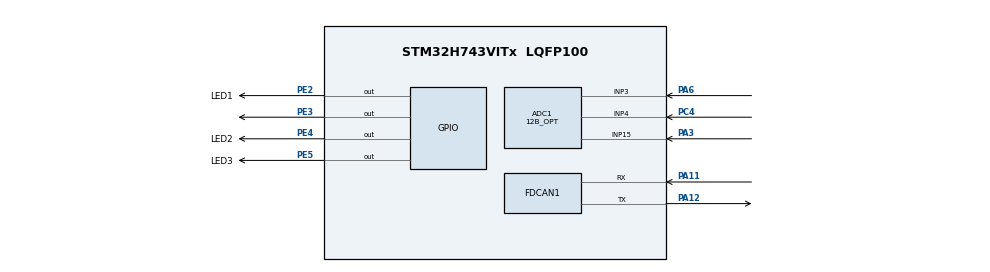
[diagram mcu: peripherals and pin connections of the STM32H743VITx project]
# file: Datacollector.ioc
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ADC1.Channel-1\#ChannelRegularConversion=ADC_CHANNEL_3
ADC1.Channel-7\#ChannelRegularConversion=ADC_CHANNEL_4
ADC1.Channel-8\#ChannelRegularConversion=ADC_CHANNEL_15
ADC1.ClockPrescaler=ADC_CLOCK_ASYNC_DIV1
ADC1.ContinuousConvMode=DISABLE
ADC1.ConversionDataManagement=ADC_CONVERSIONDATA_DMA_ONESHOT
ADC1.DiscontinuousConvMode=DISABLE
ADC1.EOCSelection=ADC_EOC_SEQ_CONV
ADC1.EnableAnalogWatchDog1=false
ADC1.ExternalTrigConv=ADC_SOFTWARE_START
ADC1.NbrOfConversion=3
ADC1.NbrOfConversionFlag=1
ADC1.OffsetNumber-1\#ChannelRegularConversion=ADC_OFFSET_NONE
ADC1.OffsetNumber-7\#ChannelRegularConversion=ADC_OFFSET_NONE
ADC1.OffsetNumber-8\#ChannelRegularConversion=ADC_OFFSET_NONE
ADC1.OffsetSignedSaturation-1\#ChannelRegularConversion=DISABLE
ADC1.Rank-1\#ChannelRegularConversion=1
ADC1.Rank-7\#ChannelRegularConversion=2
ADC1.Rank-8\#ChannelRegularConversion=3
ADC1.Resolution=ADC_RESOLUTION_12B_OPT
ADC1.SamplingTime-1\#ChannelRegularConversion=ADC_SAMPLETIME_1CYCLE_5
ADC1.SamplingTime-7\#ChannelRegularConversion=ADC_SAMPLETIME_2CYCLES_5
ADC1.SamplingTime-8\#ChannelRegularConversion=ADC_SAMPLETIME_8CYCLES_5
ADC1.master=1
Dma.ADC1.0.Direction=DMA_PERIPH_TO_MEMORY
Dma.ADC1.0.EventEnable=DISABLE
Dma.ADC1.0.FIFOMode=DMA_FIFOMODE_DISABLE
Dma.ADC1.0.Instance=DMA1_Stream0
Dma.ADC1.0.MemDataAlignment=DMA_MDATAALIGN_WORD
Dma.ADC1.0.MemInc=DMA_MINC_ENABLE
Dma.ADC1.0.Mode=DMA_CIRCULAR
Dma.ADC1.0.PeriphDataAlignment=DMA_PDATAALIGN_WORD
Dma.ADC1.0.PeriphInc=DMA_PINC_DISABLE
Dma.ADC1.0.Polarity=HAL_DMAMUX_REQ_GEN_RISING
Dma.ADC1.0.Priority=DMA_PRIORITY_LOW
Dma.ADC1.0.RequestNumber=1
Dma.ADC1.0.SignalID=NONE
Dma.ADC1.0.SyncEnable=DISABLE
Dma.ADC1.0.SyncPolarity=HAL_DMAMUX_SYNC_NO_EVENT
Dma.ADC1.0.SyncRequestNumber=1
Dma.ADC1.0.SyncSignalID=NONE
Dma.Request0=ADC1
FDCAN1.AutoRetransmission=DISABLE
FDCAN1.ClockCalibrationCCU=DISABLE
FDCAN1.DataPrescaler=1
FDCAN1.DataSyncJumpWidth=2
FDCAN1.DataTimeSeg1=13
FDCAN1.DataTimeSeg2=2
FDCAN1.FrameFormat=FDCAN_FRAME_CLASSIC
FDCAN1.NominalSyncJumpWidth=2
FDCAN1.NominalTimeSeg1=\ 13
FDCAN1.RxBuffersNbr=32
FDCAN1.RxFifo0ElmtSize=FDCAN_DATA_BYTES_8
FDCAN1.RxFifo0ElmtsNbr=32
FDCAN1.RxFifo1ElmtsNbr=32
FDCAN1.StdFiltersNbr=0
FDCAN1.TxBuffersNbr=32
FDCAN1.TxElmtSize=FDCAN_DATA_BYTES_8
FDCAN1.TxEventsNbr=32
FDCAN1.TxFifoQueueElmtsNbr=32
Mcu.Family=STM32H7
Mcu.Name=STM32H743VITx
Mcu.Package=LQFP100
NVIC.DMA1_Stream0_IRQn=true\:0\:0\:false\:false\:true\:false\:true\:true
NVIC.FDCAN1_IT0_IRQn=true\:5\:0\:true\:false\:true\:true\:true\:true
NVIC.FDCAN1_IT1_IRQn=true\:0\:0\:false\:false\:true\:true\:true\:true
NVIC.PriorityGroup=NVIC_PRIORITYGROUP_4
NVIC.TIM1_UP_IRQn=true\:0\:0\:false\:false\:true\:true\:true\:true
PA11.Mode=FDCAN_Activate
PA11.Signal=FDCAN1_RX
PA12.Mode=FDCAN_Activate
PA12.Signal=FDCAN1_TX
PA13\ (JTMS/SWDIO).Mode=Serial_Wire
PA13\ (JTMS/SWDIO).Signal=DEBUG_JTMS-SWDIO
PA14\ (JTCK/SWCLK).Mode=Serial_Wire
PA14\ (JTCK/SWCLK).Signal=DEBUG_JTCK-SWCLK
PA3.Signal=ADCx_INP15
PA6.Signal=ADCx_INP3
PC4.Signal=ADCx_INP4
PE2.GPIO_Label=LED1
PE2.Signal=GPIO_Output
PE3.Signal=GPIO_Output
PE4.GPIO_Label=LED2
PE4.Signal=GPIO_Output
PE5.GPIO_Label=LED3
PE5.Signal=GPIO_Output
PH0-OSC_IN\ (PH0).Mode=HSE-External-Oscillator
PH0-OSC_IN\ (PH0).Signal=RCC_OSC_IN
PH1-OSC_OUT\ (PH1).Mode=HSE-External-Oscillator
PH1-OSC_OUT\ (PH1).Signal=RCC_OSC_OUT
ProjectManager.HeapSize=0x200
ProjectManager.StackSize=0x400
ProjectManager.TargetToolchain=STM32CubeIDE
RCC.ADCFreq_Value=40000000
RCC.APB1Freq_Value=50000000
RCC.APB2Freq_Value=100000000
RCC.APB3Freq_Value=50000000
RCC.APB4Freq_Value=100000000
RCC.CortexFreq_Value=100000000
RCC.D1CPRE=RCC_SYSCLK_DIV2
RCC.D1PPRE=RCC_APB3_DIV2
RCC.D2PPRE1=RCC_APB1_DIV2
RCC.DIVM1=1
RCC.DIVM2=4
RCC.DIVM3=22
RCC.DIVN1=50
RCC.DIVN2=80
RCC.DIVP2=4
RCC.DIVQ1=8
RCC.DIVQ2=5
RCC.DIVR1=10
RCC.FDCANCLockSelection=RCC_FDCANCLKSOURCE_HSE
RCC.HCLKFreq_Value=100000000
RCC.HSE_VALUE=8000000
RCC.PLL2FRACN=0
RCC.PLLFRACN=0
RCC.PLLSourceVirtual=RCC_PLLSOURCE_HSE
RCC.PREFETCH_ENABLE=1
RCC.SYSCLKFreq_VALUE=200000000
RCC.SYSCLKSource=RCC_SYSCLKSOURCE_PLLCLK
RCC.USBFreq_Value=50000000
SH.ADCx_INP15.0=ADC1_INP15,IN15-Single-Ended
SH.ADCx_INP3.0=ADC1_INP3,IN3-Single-Ended
SH.ADCx_INP4.0=ADC1_INP4,IN4-Single-Ended
TIM1.AutoReloadPreload=TIM_AUTORELOAD_PRELOAD_DISABLE
TIM1.Period=1
TIM1.Prescaler=10000
TIM1.RepetitionCounter=0
TIM1.TIM_MasterOutputTrigger=TIM_TRGO_UPDATE
VP_TIM1_VS_ClockSourceINT.Mode=Internal
board=custom

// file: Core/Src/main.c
/* USER CODE BEGIN Header */
/**
 ******************************************************************************
 * @file           : main.c
 * @brief          : Main program body
 ******************************************************************************
 * @attention
 *
 * Copyright (c) 2023 STMicroelectronics.
 * All rights reserved.
 *
 * This software is licensed under terms that can be found in the LICENSE file
 * in the root directory of this software component.
 * If no LICENSE file comes with this software, it is provided AS-IS.
 *
 ******************************************************************************
 */
/* USER CODE END Header */
#include "main.h"

/* USER CODE BEGIN Includes */
#include "CAN.h"
#include "ADC.h"
/* USER CODE END Includes */

 ADC_HandleTypeDef hadc1;
DMA_HandleTypeDef hdma_adc1;

FDCAN_HandleTypeDef hfdcan1;

TIM_HandleTypeDef htim1;

/* USER CODE BEGIN PV */
ADC_ChannelConfTypeDef sConfig = { 0 };
uint16_t TxData[4];
extern uint32_t ADC_value[3];
/* USER CODE END PV */

void SystemClock_Config(void);
static void MX_GPIO_Init(void);
static void MX_DMA_Init(void);
static void MX_ADC1_Init(void);
static void MX_TIM1_Init(void);
static void MX_FDCAN1_Init(void);

int main(void)
{

  /* MCU Configuration--------------------------------------------------------*/

  /* Reset of all peripherals, Initializes the Flash interface and the Systick. */
  HAL_Init();

  /* Configure the system clock */
  SystemClock_Config();

  /* Initialize all configured peripherals */
  MX_GPIO_Init();
  MX_DMA_Init();
  MX_ADC1_Init();
  MX_TIM1_Init();
  MX_FDCAN1_Init();
  /* USER CODE BEGIN 2 */
	ADC_Init();
	CAN_Init();
  /* USER CODE END 2 */

  /* Infinite loop */
	while (1) {

    /* USER CODE BEGIN 3 */
		HAL_GPIO_TogglePin(LED1_GPIO_Port, LED1_Pin);
		TxData[0] = ADC_value[0];
		CAN_TxData(101, TxData);
		HAL_Delay(50);
	}
  /* USER CODE END 3 */
}

void SystemClock_Config(void)
{
  RCC_OscInitTypeDef RCC_OscInitStruct = {0};
  RCC_ClkInitTypeDef RCC_ClkInitStruct = {0};

  /** Supply configuration update enable
  */
  HAL_PWREx_ConfigSupply(PWR_LDO_SUPPLY);

  /** Configure the main internal regulator output voltage
  */
  __HAL_PWR_VOLTAGESCALING_CONFIG(PWR_REGULATOR_VOLTAGE_SCALE3);

  while(!__HAL_PWR_GET_FLAG(PWR_FLAG_VOSRDY)) {}

  /** Macro to configure the PLL clock source
  */
  __HAL_RCC_PLL_PLLSOURCE_CONFIG(RCC_PLLSOURCE_HSE);

  /** Initializes the RCC Oscillators according to the specified parameters
  * in the RCC_OscInitTypeDef structure.
  */
  RCC_OscInitStruct.OscillatorType = RCC_OSCILLATORTYPE_HSE;
  RCC_OscInitStruct.HSEState = RCC_HSE_ON;
  RCC_OscInitStruct.PLL.PLLState = RCC_PLL_ON;
  RCC_OscInitStruct.PLL.PLLSource = RCC_PLLSOURCE_HSE;
  RCC_OscInitStruct.PLL.PLLM = 1;
  RCC_OscInitStruct.PLL.PLLN = 50;
  RCC_OscInitStruct.PLL.PLLP = 2;
  RCC_OscInitStruct.PLL.PLLQ = 8;
  RCC_OscInitStruct.PLL.PLLR = 10;
  RCC_OscInitStruct.PLL.PLLRGE = RCC_PLL1VCIRANGE_3;
  RCC_OscInitStruct.PLL.PLLVCOSEL = RCC_PLL1VCOWIDE;
  RCC_OscInitStruct.PLL.PLLFRACN = 0;
  if (HAL_RCC_OscConfig(&RCC_OscInitStruct) != HAL_OK)
  {
    Error_Handler();
  }

  /** Initializes the CPU, AHB and APB buses clocks
  */
  RCC_ClkInitStruct.ClockType = RCC_CLOCKTYPE_HCLK|RCC_CLOCKTYPE_SYSCLK
                              |RCC_CLOCKTYPE_PCLK1|RCC_CLOCKTYPE_PCLK2
                              |RCC_CLOCKTYPE_D3PCLK1|RCC_CLOCKTYPE_D1PCLK1;
  RCC_ClkInitStruct.SYSCLKSource = RCC_SYSCLKSOURCE_PLLCLK;
  RCC_ClkInitStruct.SYSCLKDivider = RCC_SYSCLK_DIV2;
  RCC_ClkInitStruct.AHBCLKDivider = RCC_HCLK_DIV1;
  RCC_ClkInitStruct.APB3CLKDivider = RCC_APB3_DIV2;
  RCC_ClkInitStruct.APB1CLKDivider = RCC_APB1_DIV2;
  RCC_ClkInitStruct.APB2CLKDivider = RCC_APB2_DIV1;
  RCC_ClkInitStruct.APB4CLKDivider = RCC_APB4_DIV1;

  if (HAL_RCC_ClockConfig(&RCC_ClkInitStruct, FLASH_LATENCY_2) != HAL_OK)
  {
    Error_Handler();
  }
}

static void MX_ADC1_Init(void)
{

  ADC_MultiModeTypeDef multimode = {0};
  ADC_ChannelConfTypeDef sConfig = {0};

  /** Common config
  */
  hadc1.Instance = ADC1;
  hadc1.Init.ClockPrescaler = ADC_CLOCK_ASYNC_DIV1;
  hadc1.Init.Resolution = ADC_RESOLUTION_12B_OPT;
  hadc1.Init.ScanConvMode = ADC_SCAN_ENABLE;
  hadc1.Init.EOCSelection = ADC_EOC_SEQ_CONV;
  hadc1.Init.LowPowerAutoWait = DISABLE;
  hadc1.Init.ContinuousConvMode = DISABLE;
  hadc1.Init.NbrOfConversion = 3;
  hadc1.Init.DiscontinuousConvMode = DISABLE;
  hadc1.Init.ExternalTrigConv = ADC_SOFTWARE_START;
  hadc1.Init.ExternalTrigConvEdge = ADC_EXTERNALTRIGCONVEDGE_NONE;
  hadc1.Init.ConversionDataManagement = ADC_CONVERSIONDATA_DMA_ONESHOT;
  hadc1.Init.Overrun = ADC_OVR_DATA_PRESERVED;
  hadc1.Init.LeftBitShift = ADC_LEFTBITSHIFT_NONE;
  hadc1.Init.OversamplingMode = DISABLE;
  if (HAL_ADC_Init(&hadc1) != HAL_OK)
  {
    Error_Handler();
  }

  /** Configure the ADC multi-mode
  */
  multimode.Mode = ADC_MODE_INDEPENDENT;
  if (HAL_ADCEx_MultiModeConfigChannel(&hadc1, &multimode) != HAL_OK)
  {
    Error_Handler();
  }

  /** Configure Regular Channel
  */
  sConfig.Channel = ADC_CHANNEL_3;
  sConfig.Rank = ADC_REGULAR_RANK_1;
  sConfig.SamplingTime = ADC_SAMPLETIME_1CYCLE_5;
  sConfig.SingleDiff = ADC_SINGLE_ENDED;
  sConfig.OffsetNumber = ADC_OFFSET_NONE;
  sConfig.Offset = 0;
  sConfig.OffsetSignedSaturation = DISABLE;
  if (HAL_ADC_ConfigChannel(&hadc1, &sConfig) != HAL_OK)
  {
    Error_Handler();
  }

  /** Configure Regular Channel
  */
  sConfig.Channel = ADC_CHANNEL_4;
  sConfig.Rank = ADC_REGULAR_RANK_2;
  sConfig.SamplingTime = ADC_SAMPLETIME_2CYCLES_5;
  if (HAL_ADC_ConfigChannel(&hadc1, &sConfig) != HAL_OK)
  {
    Error_Handler();
  }

  /** Configure Regular Channel
  */
  sConfig.Channel = ADC_CHANNEL_15;
  sConfig.Rank = ADC_REGULAR_RANK_3;
  sConfig.SamplingTime = ADC_SAMPLETIME_8CYCLES_5;
  if (HAL_ADC_ConfigChannel(&hadc1, &sConfig) != HAL_OK)
  {
    Error_Handler();
  }

}

static void MX_FDCAN1_Init(void)
{

  hfdcan1.Instance = FDCAN1;
  hfdcan1.Init.FrameFormat = FDCAN_FRAME_CLASSIC;
  hfdcan1.Init.Mode = FDCAN_MODE_NORMAL;
  hfdcan1.Init.AutoRetransmission = DISABLE;
  hfdcan1.Init.TransmitPause = DISABLE;
  hfdcan1.Init.ProtocolException = DISABLE;
  hfdcan1.Init.NominalPrescaler = 1;
  hfdcan1.Init.NominalSyncJumpWidth = 2;
  hfdcan1.Init.NominalTimeSeg1 = 13;
  hfdcan1.Init.NominalTimeSeg2 = 2;
  hfdcan1.Init.DataPrescaler = 1;
  hfdcan1.Init.DataSyncJumpWidth = 2;
  hfdcan1.Init.DataTimeSeg1 = 13;
  hfdcan1.Init.DataTimeSeg2 = 2;
  hfdcan1.Init.MessageRAMOffset = 0;
  hfdcan1.Init.StdFiltersNbr = 0;
  hfdcan1.Init.ExtFiltersNbr = 0;
  hfdcan1.Init.RxFifo0ElmtsNbr = 32;
  hfdcan1.Init.RxFifo0ElmtSize = FDCAN_DATA_BYTES_8;
  hfdcan1.Init.RxFifo1ElmtsNbr = 32;
  hfdcan1.Init.RxFifo1ElmtSize = FDCAN_DATA_BYTES_8;
  hfdcan1.Init.RxBuffersNbr = 32;
  hfdcan1.Init.RxBufferSize = FDCAN_DATA_BYTES_8;
  hfdcan1.Init.TxEventsNbr = 32;
  hfdcan1.Init.TxBuffersNbr = 32;
  hfdcan1.Init.TxFifoQueueElmtsNbr = 32;
  hfdcan1.Init.TxFifoQueueMode = FDCAN_TX_FIFO_OPERATION;
  hfdcan1.Init.TxElmtSize = FDCAN_DATA_BYTES_8;
  if (HAL_FDCAN_Init(&hfdcan1) != HAL_OK)
  {
    Error_Handler();
  }

}

static void MX_TIM1_Init(void)
{

  TIM_ClockConfigTypeDef sClockSourceConfig = {0};
  TIM_MasterConfigTypeDef sMasterConfig = {0};

  htim1.Instance = TIM1;
  htim1.Init.Prescaler = 10000;
  htim1.Init.CounterMode = TIM_COUNTERMODE_UP;
  htim1.Init.Period = 1;
  htim1.Init.ClockDivision = TIM_CLOCKDIVISION_DIV1;
  htim1.Init.RepetitionCounter = 0;
  htim1.Init.AutoReloadPreload = TIM_AUTORELOAD_PRELOAD_DISABLE;
  if (HAL_TIM_Base_Init(&htim1) != HAL_OK)
  {
    Error_Handler();
  }
  sClockSourceConfig.ClockSource = TIM_CLOCKSOURCE_INTERNAL;
  if (HAL_TIM_ConfigClockSource(&htim1, &sClockSourceConfig) != HAL_OK)
  {
    Error_Handler();
  }
  sMasterConfig.MasterOutputTrigger = TIM_TRGO_UPDATE;
  sMasterConfig.MasterOutputTrigger2 = TIM_TRGO2_RESET;
  sMasterConfig.MasterSlaveMode = TIM_MASTERSLAVEMODE_DISABLE;
  if (HAL_TIMEx_MasterConfigSynchronization(&htim1, &sMasterConfig) != HAL_OK)
  {
    Error_Handler();
  }

}

static void MX_DMA_Init(void)
{

  /* DMA controller clock enable */
  __HAL_RCC_DMA1_CLK_ENABLE();

  /* DMA interrupt init */
  /* DMA1_Stream0_IRQn interrupt configuration */
  HAL_NVIC_SetPriority(DMA1_Stream0_IRQn, 0, 0);
  HAL_NVIC_EnableIRQ(DMA1_Stream0_IRQn);

}

static void MX_GPIO_Init(void)
{
  GPIO_InitTypeDef GPIO_InitStruct = {0};

  /* GPIO Ports Clock Enable */
  __HAL_RCC_GPIOE_CLK_ENABLE();
  __HAL_RCC_GPIOH_CLK_ENABLE();
  __HAL_RCC_GPIOA_CLK_ENABLE();
  __HAL_RCC_GPIOC_CLK_ENABLE();

  /*Configure GPIO pin Output Level */
  HAL_GPIO_WritePin(GPIOE, LED1_Pin|GPIO_PIN_3|LED2_Pin|LED3_Pin, GPIO_PIN_RESET);

  /*Configure GPIO pins : LED1_Pin PE3 LED2_Pin LED3_Pin */
  GPIO_InitStruct.Pin = LED1_Pin|GPIO_PIN_3|LED2_Pin|LED3_Pin;
  GPIO_InitStruct.Mode = GPIO_MODE_OUTPUT_PP;
  GPIO_InitStruct.Pull = GPIO_NOPULL;
  GPIO_InitStruct.Speed = GPIO_SPEED_FREQ_LOW;
  HAL_GPIO_Init(GPIOE, &GPIO_InitStruct);

}

void Error_Handler(void)
{
  /* USER CODE BEGIN Error_Handler_Debug */
	/* User can add his own implementation to report the HAL error return state */
	__disable_irq();
	HAL_GPIO_WritePin(GPIOE, GPIO_PIN_5, GPIO_PIN_SET);
  /* USER CODE END Error_Handler_Debug */
}
